VERSION ""

NS_ :

BS_:

BU_: Allradsteuerung Anhaengersteuerung Bremsregelung Daempferregelung Fahrwerk Hinterachslenkung Lenkung Reifendruckkontrolle System

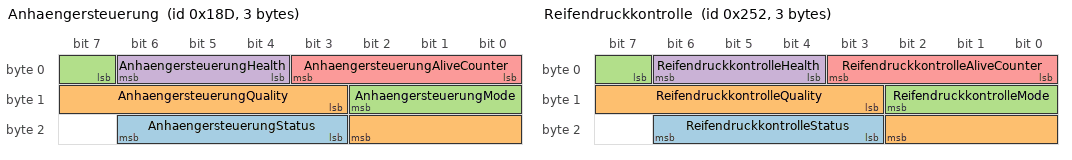
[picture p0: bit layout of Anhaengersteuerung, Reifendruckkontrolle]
BO_ 397 Anhaengersteuerung: 3 Anhaengersteuerung
 SG_ AnhaengersteuerungStatus : 19|4@1+ (1,0) [0.0|15.0] "code"  System
 SG_ AnhaengersteuerungQuality : 11|8@1+ (0.5,0.0) [0.0|100.0] "%"  System
 SG_ AnhaengersteuerungMode : 7|4@1+ (1,0) [0.0|15.0] "code"  System
 SG_ AnhaengersteuerungHealth : 4|3@1+ (1,0) [0.0|7.0] "code"  System
 SG_ AnhaengersteuerungAliveCounter : 0|4@1+ (1,0) [0.0|15.0] "count"  System

BO_ 594 Reifendruckkontrolle: 3 Reifendruckkontrolle
 SG_ ReifendruckkontrolleStatus : 19|4@1+ (1,0) [0.0|15.0] "code"  System
 SG_ ReifendruckkontrolleQuality : 11|8@1+ (0.5,0.0) [0.0|100.0] "%"  System
 SG_ ReifendruckkontrolleMode : 7|4@1+ (1,0) [0.0|15.0] "code"  System
 SG_ ReifendruckkontrolleHealth : 4|3@1+ (1,0) [0.0|7.0] "code"  System
 SG_ ReifendruckkontrolleAliveCounter : 0|4@1+ (1,0) [0.0|15.0] "count"  System

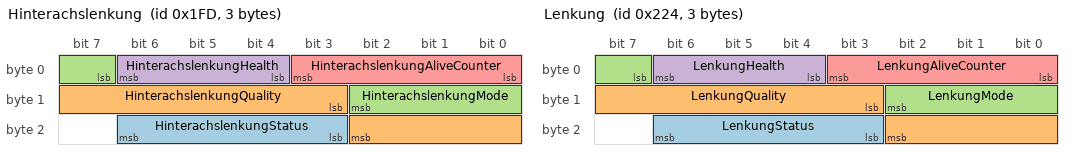
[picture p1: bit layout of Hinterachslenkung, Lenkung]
BO_ 509 Hinterachslenkung: 3 Hinterachslenkung
 SG_ HinterachslenkungStatus : 19|4@1+ (1,0) [0.0|15.0] "code"  System
 SG_ HinterachslenkungQuality : 11|8@1+ (0.5,0.0) [0.0|100.0] "%"  System
 SG_ HinterachslenkungMode : 7|4@1+ (1,0) [0.0|15.0] "code"  System
 SG_ HinterachslenkungHealth : 4|3@1+ (1,0) [0.0|7.0] "code"  System
 SG_ HinterachslenkungAliveCounter : 0|4@1+ (1,0) [0.0|15.0] "count"  System

BO_ 548 Lenkung: 3 Lenkung
 SG_ LenkungStatus : 19|4@1+ (1,0) [0.0|15.0] "code"  System
 SG_ LenkungQuality : 11|8@1+ (0.5,0.0) [0.0|100.0] "%"  System
 SG_ LenkungMode : 7|4@1+ (1,0) [0.0|15.0] "code"  System
 SG_ LenkungHealth : 4|3@1+ (1,0) [0.0|7.0] "code"  System
 SG_ LenkungAliveCounter : 0|4@1+ (1,0) [0.0|15.0] "count"  System

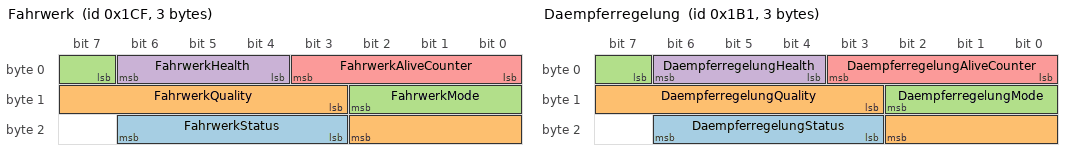
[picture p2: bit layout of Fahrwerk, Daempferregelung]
BO_ 463 Fahrwerk: 3 Fahrwerk
 SG_ FahrwerkStatus : 19|4@1+ (1,0) [0.0|15.0] "code"  System
 SG_ FahrwerkQuality : 11|8@1+ (0.5,0.0) [0.0|100.0] "%"  System
 SG_ FahrwerkMode : 7|4@1+ (1,0) [0.0|15.0] "code"  System
 SG_ FahrwerkHealth : 4|3@1+ (1,0) [0.0|7.0] "code"  System
 SG_ FahrwerkAliveCounter : 0|4@1+ (1,0) [0.0|15.0] "count"  System

BO_ 433 Daempferregelung: 3 Daempferregelung
 SG_ DaempferregelungStatus : 19|4@1+ (1,0) [0.0|15.0] "code"  System
 SG_ DaempferregelungQuality : 11|8@1+ (0.5,0.0) [0.0|100.0] "%"  System
 SG_ DaempferregelungMode : 7|4@1+ (1,0) [0.0|15.0] "code"  System
 SG_ DaempferregelungHealth : 4|3@1+ (1,0) [0.0|7.0] "code"  System
 SG_ DaempferregelungAliveCounter : 0|4@1+ (1,0) [0.0|15.0] "count"  System

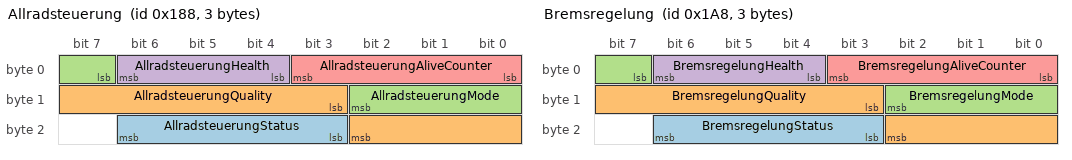
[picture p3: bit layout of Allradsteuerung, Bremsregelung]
BO_ 392 Allradsteuerung: 3 Allradsteuerung
 SG_ AllradsteuerungStatus : 19|4@1+ (1,0) [0.0|15.0] "code"  System
 SG_ AllradsteuerungQuality : 11|8@1+ (0.5,0.0) [0.0|100.0] "%"  System
 SG_ AllradsteuerungMode : 7|4@1+ (1,0) [0.0|15.0] "code"  System
 SG_ AllradsteuerungHealth : 4|3@1+ (1,0) [0.0|7.0] "code"  System
 SG_ AllradsteuerungAliveCounter : 0|4@1+ (1,0) [0.0|15.0] "count"  System

BO_ 424 Bremsregelung: 3 Bremsregelung
 SG_ BremsregelungStatus : 19|4@1+ (1,0) [0.0|15.0] "code"  System
 SG_ BremsregelungQuality : 11|8@1+ (0.5,0.0) [0.0|100.0] "%"  System
 SG_ BremsregelungMode : 7|4@1+ (1,0) [0.0|15.0] "code"  System
 SG_ BremsregelungHealth : 4|3@1+ (1,0) [0.0|7.0] "code"  System
 SG_ BremsregelungAliveCounter : 0|4@1+ (1,0) [0.0|15.0] "count"  System

CM_ BO_ 397 "CanonicalMessage=a0b9406e-eb1e-47f4-8e6b-05541363e8ff; Network=Fahrwerk_Fahrdynamik_03-S01; Technology=can_fd";
CM_ SG_ 397 AnhaengersteuerungStatus "CanonicalSignal=932cc671-3884-423b-9d01-81e8bab4e5f0";
CM_ SG_ 397 AnhaengersteuerungQuality "CanonicalSignal=7ae57fc4-fda5-47e0-a536-ddd9cfdc93e1";
CM_ SG_ 397 AnhaengersteuerungMode "CanonicalSignal=6efc1668-224b-4b4d-aa2e-dabdfa987ce1";
CM_ SG_ 397 AnhaengersteuerungHealth "CanonicalSignal=2bb2aada-6f92-41e3-9439-ab536a9436dc";
CM_ SG_ 397 AnhaengersteuerungAliveCounter "CanonicalSignal=c6cf37f4-a1b6-41a9-b2da-1d62ad190cde";
CM_ BO_ 594 "CanonicalMessage=476b7826-71ef-4adc-9803-4dc16231026f; Network=Fahrwerk_Fahrdynamik_03-S01; Technology=can_fd";
CM_ SG_ 594 ReifendruckkontrolleStatus "CanonicalSignal=4687804f-853c-4219-8b54-26873a0e4cc9";
CM_ SG_ 594 ReifendruckkontrolleQuality "CanonicalSignal=d2a3ab65-ba60-4bcd-84ef-8b8c28152e58";
CM_ SG_ 594 ReifendruckkontrolleMode "CanonicalSignal=404a245b-aacb-4d63-a8bf-db546b46e43c";
CM_ SG_ 594 ReifendruckkontrolleHealth "CanonicalSignal=5617e620-8034-4c43-ab0a-5188ce43c1a4";
CM_ SG_ 594 ReifendruckkontrolleAliveCounter "CanonicalSignal=e923b343-e864-4507-b480-bca3183f2d53";
CM_ BO_ 509 "CanonicalMessage=d8a5ce91-f92b-4da8-8149-50a10b552060; Network=Fahrwerk_Fahrdynamik_03-S01; Technology=can_fd";
CM_ SG_ 509 HinterachslenkungStatus "CanonicalSignal=173edb36-cff6-4836-a593-34b6857e72f5";
CM_ SG_ 509 HinterachslenkungQuality "CanonicalSignal=a68d3a25-3850-4e0d-aaf8-a9e75127a92f";
CM_ SG_ 509 HinterachslenkungMode "CanonicalSignal=7f9a3eca-a620-4ab6-a7ba-674b15f1bacb";
CM_ SG_ 509 HinterachslenkungHealth "CanonicalSignal=14d1dcac-1ea0-4ee8-9428-b4bef8b84e1b";
CM_ SG_ 509 HinterachslenkungAliveCounter "CanonicalSignal=da24c852-961c-48ab-8b0f-91895f280357";
CM_ BO_ 548 "CanonicalMessage=58163e25-6d1e-4574-a782-e74768e98cc9; Network=Fahrwerk_Fahrdynamik_03-S01; Technology=can_fd";
CM_ SG_ 548 LenkungStatus "CanonicalSignal=5b2e0814-3ec3-4e2d-94e5-8b2469d7ed10";
CM_ SG_ 548 LenkungQuality "CanonicalSignal=c718a60d-92ef-4cc5-bc4f-a7c549ac26eb";
CM_ SG_ 548 LenkungMode "CanonicalSignal=5635e1f7-b9c6-41b4-8ce5-87c91a1a4b30";
CM_ SG_ 548 LenkungHealth "CanonicalSignal=1f05d96e-3fbe-4502-8eb7-5c046b10489a";
CM_ SG_ 548 LenkungAliveCounter "CanonicalSignal=c6b6848d-fa10-4239-bf77-db06701f212e";
CM_ BO_ 463 "CanonicalMessage=a271cffb-3d03-4c2b-a40d-120689d5a0e6; Network=Fahrwerk_Fahrdynamik_03-S01; Technology=can_fd";
CM_ SG_ 463 FahrwerkStatus "CanonicalSignal=f7b02b41-6fd1-494a-ae98-0c95284bf3d6";
CM_ SG_ 463 FahrwerkQuality "CanonicalSignal=712918e1-22bc-42c9-b632-1beae58e7566";
CM_ SG_ 463 FahrwerkMode "CanonicalSignal=7ba615a2-eedc-49ad-84a1-89fe3a34651b";
CM_ SG_ 463 FahrwerkHealth "CanonicalSignal=d41773af-9122-46b4-acc6-5232fe3d6b6a";
CM_ SG_ 463 FahrwerkAliveCounter "CanonicalSignal=f97b1497-ede8-4c0d-ba1e-e336aa1076bb";
CM_ BO_ 433 "CanonicalMessage=b3be7bb1-5811-4a80-af53-873f527b3ebe; Network=Fahrwerk_Fahrdynamik_03-S01; Technology=can_fd";
CM_ SG_ 433 DaempferregelungStatus "CanonicalSignal=91ef8ae4-4c07-4f5c-9428-2069b9565c07";
CM_ SG_ 433 DaempferregelungQuality "CanonicalSignal=10aa3660-ce60-4e7d-944c-39ab2e78acdb";
CM_ SG_ 433 DaempferregelungMode "CanonicalSignal=cf56a6c6-e10c-4dce-b3fe-46230d919573";
CM_ SG_ 433 DaempferregelungHealth "CanonicalSignal=91597973-a5a7-4cfa-bc24-251c49eb4e20";
CM_ SG_ 433 DaempferregelungAliveCounter "CanonicalSignal=1d69f8f6-69ba-4794-b885-3cd72b087ae2";
CM_ BO_ 392 "CanonicalMessage=1b19d29c-3a7d-4f16-8623-b9d1ab4f1734; Network=Fahrwerk_Fahrdynamik_03-S01; Technology=can_fd";
CM_ SG_ 392 AllradsteuerungStatus "CanonicalSignal=84e8168b-348b-4fd2-8a5d-02203daed08e";
CM_ SG_ 392 AllradsteuerungQuality "CanonicalSignal=ed3eba49-00a4-4971-8a18-bedfc151c3a5";
CM_ SG_ 392 AllradsteuerungMode "CanonicalSignal=eb508aae-1c64-4d8a-b57e-8a02d8795f6d";
CM_ SG_ 392 AllradsteuerungHealth "CanonicalSignal=f5a75ba0-fe7e-4be1-af2d-d060e5f2a4b3";
CM_ SG_ 392 AllradsteuerungAliveCounter "CanonicalSignal=4415b534-4d9c-4e56-a10c-91497955706d";
CM_ BO_ 424 "CanonicalMessage=a8dc0bfa-02f0-4015-82e1-1f90b1d8825f; Network=Fahrwerk_Fahrdynamik_03-S01; Technology=can_fd";
CM_ SG_ 424 BremsregelungStatus "CanonicalSignal=6089751f-e8e3-43e5-8d4b-c43e6436a39e";
CM_ SG_ 424 BremsregelungQuality "CanonicalSignal=d877e2eb-8136-4303-b138-7551fcafe8c1";
CM_ SG_ 424 BremsregelungMode "CanonicalSignal=5453cc66-5661-4641-8654-0ea9ed059cb5";
CM_ SG_ 424 BremsregelungHealth "CanonicalSignal=66216c18-d25f-46ab-9e8e-1ab543d127d2";
CM_ SG_ 424 BremsregelungAliveCounter "CanonicalSignal=c1f21296-aec4-45bd-9a19-6100c83902e7";
BA_DEF_ BO_  "VFrameFormat" ENUM  "StandardCAN","ExtendedCAN","StandardCAN_FD","ExtendedCAN_FD";
BA_DEF_DEF_  "VFrameFormat" "0";
BA_ "VFrameFormat" BO_ 397 2;
BA_ "VFrameFormat" BO_ 594 2;
BA_ "VFrameFormat" BO_ 509 2;
BA_ "VFrameFormat" BO_ 548 2;
BA_ "VFrameFormat" BO_ 463 2;
BA_ "VFrameFormat" BO_ 433 2;
BA_ "VFrameFormat" BO_ 392 2;
BA_ "VFrameFormat" BO_ 424 2;
